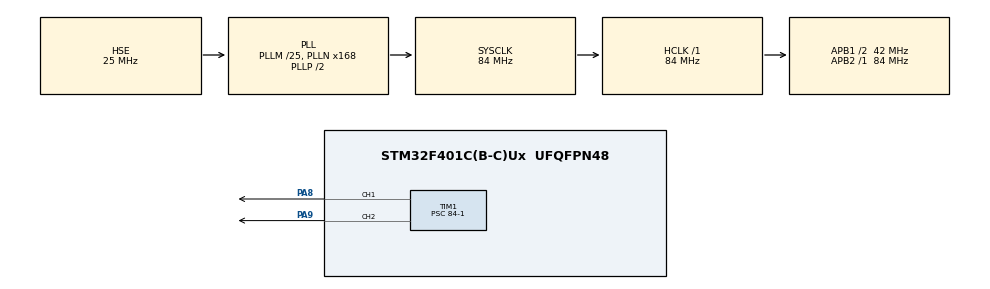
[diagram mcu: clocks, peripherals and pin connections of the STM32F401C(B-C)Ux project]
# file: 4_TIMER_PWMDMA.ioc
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Dma.Request0=TIM1_CH1
Dma.TIM1_CH1.0.Direction=DMA_PERIPH_TO_MEMORY
Dma.TIM1_CH1.0.FIFOMode=DMA_FIFOMODE_DISABLE
Dma.TIM1_CH1.0.Instance=DMA2_Stream1
Dma.TIM1_CH1.0.MemDataAlignment=DMA_MDATAALIGN_HALFWORD
Dma.TIM1_CH1.0.MemInc=DMA_MINC_ENABLE
Dma.TIM1_CH1.0.Mode=DMA_NORMAL
Dma.TIM1_CH1.0.PeriphDataAlignment=DMA_PDATAALIGN_HALFWORD
Dma.TIM1_CH1.0.PeriphInc=DMA_PINC_DISABLE
Dma.TIM1_CH1.0.Priority=DMA_PRIORITY_LOW
Mcu.Family=STM32F4
Mcu.Name=STM32F401C(B-C)Ux
Mcu.Package=UFQFPN48
NVIC.DMA2_Stream1_IRQn=true\:0\:0\:false\:false\:true\:false\:true
NVIC.PriorityGroup=NVIC_PRIORITYGROUP_4
PA13.Mode=Serial_Wire
PA13.Signal=SYS_JTMS-SWDIO
PA14.Mode=Serial_Wire
PA14.Signal=SYS_JTCK-SWCLK
PA8.Signal=S_TIM1_CH1
PA9.Signal=S_TIM1_CH2
PH0\ -\ OSC_IN.Mode=HSE-External-Oscillator
PH0\ -\ OSC_IN.Signal=RCC_OSC_IN
PH1\ -\ OSC_OUT.Mode=HSE-External-Oscillator
PH1\ -\ OSC_OUT.Signal=RCC_OSC_OUT
ProjectManager.HeapSize=0x200
ProjectManager.StackSize=0x400
ProjectManager.TargetToolchain=STM32CubeIDE
RCC.48MHZClocksFreq_Value=42000000
RCC.AHBFreq_Value=84000000
RCC.APB1CLKDivider=RCC_HCLK_DIV2
RCC.APB1Freq_Value=42000000
RCC.APB1TimFreq_Value=84000000
RCC.APB2Freq_Value=84000000
RCC.APB2TimFreq_Value=84000000
RCC.CortexFreq_Value=84000000
RCC.HCLKFreq_Value=84000000
RCC.HSE_VALUE=25000000
RCC.HSI_VALUE=16000000
RCC.LSE_VALUE=32768
RCC.PLLM=25
RCC.PLLN=168
RCC.PLLSourceVirtual=RCC_PLLSOURCE_HSE
RCC.SYSCLKFreq_VALUE=84000000
RCC.SYSCLKSource=RCC_SYSCLKSOURCE_PLLCLK
RCC.VCOOutputFreq_Value=168000000
SH.S_TIM1_CH1.0=TIM1_CH1,PWM Generation1 CH1
SH.S_TIM1_CH2.0=TIM1_CH2,PWM Generation2 CH2
TIM1.AutoReloadPreload=TIM_AUTORELOAD_PRELOAD_ENABLE
TIM1.Channel-PWM\ Generation1\ CH1=TIM_CHANNEL_1
TIM1.Channel-PWM\ Generation2\ CH2=TIM_CHANNEL_2
TIM1.Period=1000-1
TIM1.Prescaler=84-1
TIM1.TIM_MasterOutputTrigger=TIM_TRGO_UPDATE
VP_TIM1_VS_ClockSourceINT.Mode=Internal
board=custom

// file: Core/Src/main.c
/* USER CODE BEGIN Header */
/**
  ******************************************************************************
  * @file           : main.c
  * @brief          : Main program body
  ******************************************************************************
  * @attention
  *
  * Copyright (c) 2022 STMicroelectronics.
  * All rights reserved.
  *
  * This software is licensed under terms that can be found in the LICENSE file
  * in the root directory of this software component.
  * If no LICENSE file comes with this software, it is provided AS-IS.
  *
  ******************************************************************************
  */
/* USER CODE END Header */
#include "main.h"
#include "dma.h"
#include "tim.h"
#include "gpio.h"

/* USER CODE BEGIN PV */
uint16_t pwmData[2];
/* USER CODE END PV */

void SystemClock_Config(void);

int main(void)
{

  /* MCU Configuration--------------------------------------------------------*/

  /* Reset of all peripherals, Initializes the Flash interface and the Systick. */
  HAL_Init();

  /* Configure the system clock */
  SystemClock_Config();

  /* Initialize all configured peripherals */
  MX_GPIO_Init();
  MX_DMA_Init();
  MX_TIM1_Init();
  /* USER CODE BEGIN 2 */
  HAL_TIM_Base_Start_DMA(&htim1, (uint32_t *)&pwmData[0], 1);
  HAL_TIM_Base_Start_DMA(&htim1, (uint32_t *)&pwmData[1], 1);
  /* USER CODE END 2 */

  /* Infinite loop */
  while (1)
  {

    /* USER CODE BEGIN 3 */
	  for (int i = 0; i < 1000; i++) {
		  pwmData[0] = i;
		  pwmData[1] = 1000 - i;
		  HAL_Delay(1);
	  }

	  for (int i = 1000; i > 0; i--) {
		  pwmData[0] = i;
		  pwmData[1] = 1000 - i;
		  HAL_Delay(1);
	  }

	  HAL_Delay(1000);
  }
  /* USER CODE END 3 */
}

void SystemClock_Config(void)
{
  RCC_OscInitTypeDef RCC_OscInitStruct = {0};
  RCC_ClkInitTypeDef RCC_ClkInitStruct = {0};

  /** Configure the main internal regulator output voltage
  */
  __HAL_RCC_PWR_CLK_ENABLE();
  __HAL_PWR_VOLTAGESCALING_CONFIG(PWR_REGULATOR_VOLTAGE_SCALE2);
  /** Initializes the RCC Oscillators according to the specified parameters
  * in the RCC_OscInitTypeDef structure.
  */
  RCC_OscInitStruct.OscillatorType = RCC_OSCILLATORTYPE_HSE;
  RCC_OscInitStruct.HSEState = RCC_HSE_ON;
  RCC_OscInitStruct.PLL.PLLState = RCC_PLL_ON;
  RCC_OscInitStruct.PLL.PLLSource = RCC_PLLSOURCE_HSE;
  RCC_OscInitStruct.PLL.PLLM = 25;
  RCC_OscInitStruct.PLL.PLLN = 168;
  RCC_OscInitStruct.PLL.PLLP = RCC_PLLP_DIV2;
  RCC_OscInitStruct.PLL.PLLQ = 4;
  if (HAL_RCC_OscConfig(&RCC_OscInitStruct) != HAL_OK)
  {
    Error_Handler();
  }
  /** Initializes the CPU, AHB and APB buses clocks
  */
  RCC_ClkInitStruct.ClockType = RCC_CLOCKTYPE_HCLK|RCC_CLOCKTYPE_SYSCLK
                              |RCC_CLOCKTYPE_PCLK1|RCC_CLOCKTYPE_PCLK2;
  RCC_ClkInitStruct.SYSCLKSource = RCC_SYSCLKSOURCE_PLLCLK;
  RCC_ClkInitStruct.AHBCLKDivider = RCC_SYSCLK_DIV1;
  RCC_ClkInitStruct.APB1CLKDivider = RCC_HCLK_DIV2;
  RCC_ClkInitStruct.APB2CLKDivider = RCC_HCLK_DIV1;

  if (HAL_RCC_ClockConfig(&RCC_ClkInitStruct, FLASH_LATENCY_2) != HAL_OK)
  {
    Error_Handler();
  }
}

void Error_Handler(void)
{
  __disable_irq();
  while (1)
  {
  }
}
